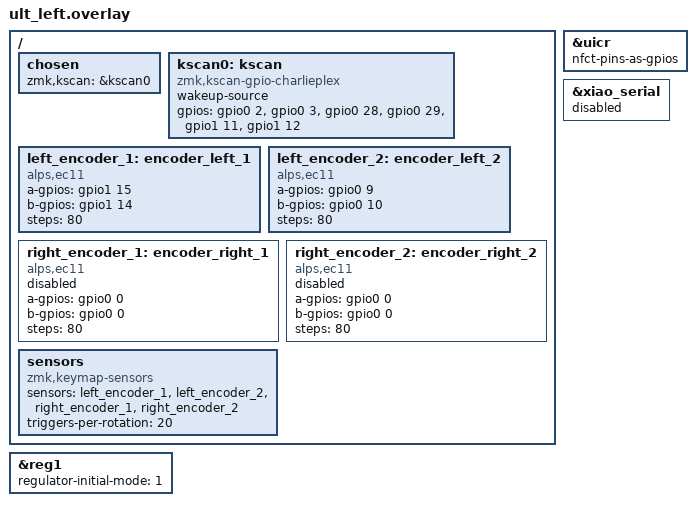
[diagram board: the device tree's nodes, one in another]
#include <dt-bindings/zmk/matrix_transform.h>
#include "ult.dtsi"

&uicr { nfct-pins-as-gpios; };
&reg1 { regulator-initial-mode = <1>; };
&xiao_serial { status = "disabled"; };

/ {
    chosen {
        zmk,kscan = &kscan0;
    };

    kscan0: kscan {
        compatible = "zmk,kscan-gpio-charlieplex";
        wakeup-source;
        gpios = <&gpio0 2  GPIO_ACTIVE_HIGH>, // IO 0
                <&gpio0 3  GPIO_ACTIVE_HIGH>, // IO 1
                <&gpio0 28 GPIO_ACTIVE_HIGH>, // IO 2
                <&gpio0 29 GPIO_ACTIVE_HIGH>, // IO 3
                <&gpio1 11 GPIO_ACTIVE_HIGH>, // IO 4
                <&gpio1 12 GPIO_ACTIVE_HIGH>; // IO 5
    };

    /* --- 左側エンコーダー (実体) --- */
    left_encoder_1: encoder_left_1 {
        compatible = "alps,ec11";
        a-gpios = <&gpio1 15 (GPIO_ACTIVE_HIGH | GPIO_PULL_UP)>;
        b-gpios = <&gpio1 14 (GPIO_ACTIVE_HIGH | GPIO_PULL_UP)>;
        steps = <80>;
        status = "okay";
    };

    left_encoder_2: encoder_left_2 {
        compatible = "alps,ec11";
        a-gpios = <&gpio0 9  (GPIO_ACTIVE_HIGH | GPIO_PULL_UP)>;
        b-gpios = <&gpio0 10 (GPIO_ACTIVE_HIGH | GPIO_PULL_UP)>;
        steps = <80>;
        status = "okay";
    };

    /* --- 右側エンコーダー (ダミー: ビルドエラー回避用) --- */
    right_encoder_1: encoder_right_1 {
        compatible = "alps,ec11";
        a-gpios = <&gpio0 0 (GPIO_ACTIVE_HIGH | GPIO_PULL_UP)>; /* ダミーピン */
        b-gpios = <&gpio0 0 (GPIO_ACTIVE_HIGH | GPIO_PULL_UP)>;
        steps = <80>;
        status = "disabled"; /* 無効化 */
    };

    right_encoder_2: encoder_right_2 {
        compatible = "alps,ec11";
        a-gpios = <&gpio0 0 (GPIO_ACTIVE_HIGH | GPIO_PULL_UP)>;
        b-gpios = <&gpio0 0 (GPIO_ACTIVE_HIGH | GPIO_PULL_UP)>;
        steps = <80>;
        status = "disabled";
    };

    /* センサーリストには全て記載する */
    sensors: sensors {
        compatible = "zmk,keymap-sensors";
        sensors = <&left_encoder_1 &left_encoder_2 &right_encoder_1 &right_encoder_2>;
        triggers-per-rotation = <20>;
    };
};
